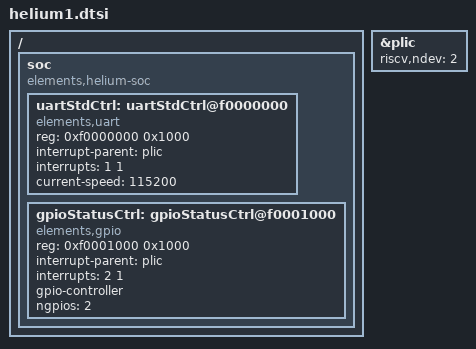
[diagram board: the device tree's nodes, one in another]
/*
 * Copyright (c) 2023 aesc silicon
 *
 * SPDX-License-Identifier: Apache-2.0
 */

#include <elements/helium.dtsi>
#include <zephyr/dt-bindings/i2c/i2c.h>

/ {
	#address-cells = <1>;
	#size-cells = <1>;

	soc {
		#address-cells = <1>;
		#size-cells = <1>;
		compatible = "elements,helium-soc", "simple-bus";
		ranges;

		uartStdCtrl: uartStdCtrl@f0000000 {
			compatible = "elements,uart";
			reg = <0xf0000000 0x1000>;
			status = "okay";
			interrupt-parent = <&plic>;
			interrupts = <1 1>;
			current-speed = <115200>;
		};

		gpioStatusCtrl: gpioStatusCtrl@f0001000 {
			compatible = "elements,gpio";
			reg = <0xf0001000 0x1000>;
			status = "okay";
			interrupt-parent = <&plic>;
			interrupts = <2 1>;
			gpio-controller;
			#gpio-cells = <2>;
			ngpios = <2>;
		};
	};
};

&plic {
	riscv,ndev = <2>;
};
